# hib register map
Vendor: Texas Instruments
Peripheral module from a debugger description file (folder tm4e1111e6zrb).
Registers are 32-bit, read-write, no defined reset value unless marked. A register's access mark holds for its fields unless they carry their own. Offsets are as the file gives them; lines under a group give offsets from that group; [hi:lo] are bit positions; {n}, {i} and the like mark numbered series; 'fields as' and 'values as' point back to an identical list; <NAME> marks a mode.

## HIB — Hibernation module register addresses
0x00 HIB_RTCC ro — Hibernation RTC Counter
  [31:0] HIB_RTCC — RTC Counter
0x04 HIB_RTCM0 — Hibernation RTC Match 0
  [31:0] HIB_RTCM0 — RTC Match 0
0x0C HIB_RTCLD — Hibernation RTC Load
  [31:0] HIB_RTCLD — RTC Load
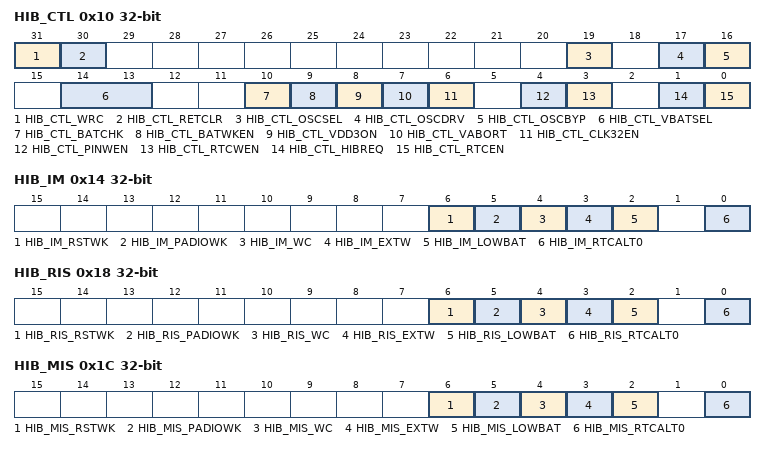
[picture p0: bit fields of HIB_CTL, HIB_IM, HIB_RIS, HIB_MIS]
0x10 HIB_CTL — Hibernation Control
  [31] HIB_CTL_WRC — Write Complete/Capable
  [30] HIB_CTL_RETCLR — GPIO Retention/Clear
  [19] HIB_CTL_OSCSEL — Oscillator Select
  [17] HIB_CTL_OSCDRV — Oscillator Drive Capability
  [16] HIB_CTL_OSCBYP — Oscillator Bypass
  [14:13] HIB_CTL_VBATSEL — Select for Low-Battery Comparator
    0=HIB_CTL_VBATSEL_1_9V (1.9 Volts); 1=HIB_CTL_VBATSEL_2_1V (2.1 Volts (default)); 2=HIB_CTL_VBATSEL_2_3V (2.3 Volts); 3=HIB_CTL_VBATSEL_2_5V (2.5 Volts)
  [10] HIB_CTL_BATCHK — Check Battery Status
  [9] HIB_CTL_BATWKEN — Wake on Low Battery
  [8] HIB_CTL_VDD3ON — VDD Powered
  [7] HIB_CTL_VABORT — Power Cut Abort Enable
  [6] HIB_CTL_CLK32EN — Clocking Enable
  [4] HIB_CTL_PINWEN — External Wake Pin Enable
  [3] HIB_CTL_RTCWEN — RTC Wake-up Enable
  [1] HIB_CTL_HIBREQ — Hibernation Request
  [0] HIB_CTL_RTCEN — RTC Timer Enable
0x14 HIB_IM — Hibernation Interrupt Mask
  [6] HIB_IM_RSTWK — Reset Pad I/O Wake-Up Interrupt Mask
  [5] HIB_IM_PADIOWK — Pad I/O Wake-Up Interrupt Mask
  [4] HIB_IM_WC — External Write Complete/Capable Interrupt Mask
  [3] HIB_IM_EXTW — External Wake-Up Interrupt Mask
  [2] HIB_IM_LOWBAT — Low Battery Voltage Interrupt Mask
  [0] HIB_IM_RTCALT0 — RTC Alert 0 Interrupt Mask
0x18 HIB_RIS ro — Hibernation Raw Interrupt Status
  [6] HIB_RIS_RSTWK — Reset Pad I/O Wake-Up Raw Interrupt Status
  [5] HIB_RIS_PADIOWK — Pad I/O Wake-Up Raw Interrupt Status
  [4] HIB_RIS_WC — Write Complete/Capable Raw Interrupt Status
  [3] HIB_RIS_EXTW — External Wake-Up Raw Interrupt Status
  [2] HIB_RIS_LOWBAT — Low Battery Voltage Raw Interrupt Status
  [0] HIB_RIS_RTCALT0 — RTC Alert 0 Raw Interrupt Status
0x1C HIB_MIS ro — Hibernation Masked Interrupt Status
  [6] HIB_MIS_RSTWK — Reset Pad I/O Wake-Up Interrupt Mask
  [5] HIB_MIS_PADIOWK — Pad I/O Wake-Up Interrupt Mask
  [4] HIB_MIS_WC — Write Complete/Capable Masked Interrupt Status
  [3] HIB_MIS_EXTW — External Wake-Up Masked Interrupt Status
  [2] HIB_MIS_LOWBAT — Low Battery Voltage Masked Interrupt Status
  [0] HIB_MIS_RTCALT0 — RTC Alert 0 Masked Interrupt Status
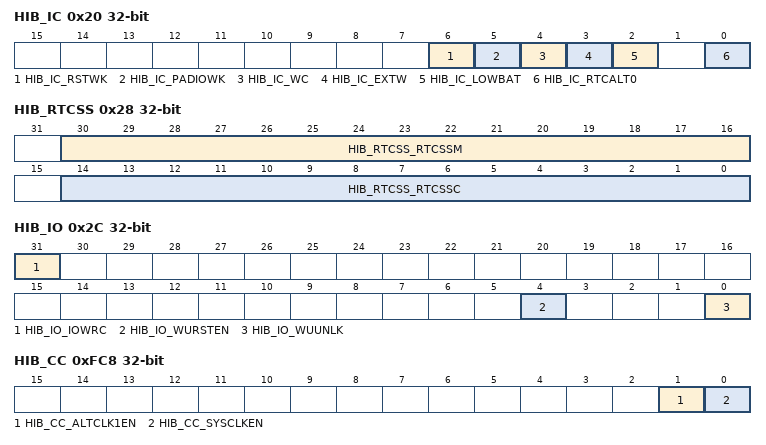
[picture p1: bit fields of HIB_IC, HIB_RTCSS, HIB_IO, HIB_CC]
0x20 HIB_IC — Hibernation Interrupt Clear
  [6] HIB_IC_RSTWK — Reset Pad I/O Wake-Up Interrupt Clear
  [5] HIB_IC_PADIOWK — Pad I/O Wake-Up Interrupt Clear
  [4] HIB_IC_WC — Write Complete/Capable Interrupt Clear
  [3] HIB_IC_EXTW — External Wake-Up Interrupt Clear
  [2] HIB_IC_LOWBAT — Low Battery Voltage Interrupt Clear
  [0] HIB_IC_RTCALT0 — RTC Alert0 Masked Interrupt Clear
0x24 HIB_RTCT — Hibernation RTC Trim
  [15:0] HIB_RTCT_TRIM — RTC Trim Value
0x28 HIB_RTCSS — Hibernation RTC Sub Seconds
  [30:16] HIB_RTCSS_RTCSSM — RTC Sub Seconds Match
  [14:0] HIB_RTCSS_RTCSSC — RTC Sub Seconds Count
0x2C HIB_IO — Hibernation IO Configuration
  [31] HIB_IO_IOWRC — I/O Write Complete
  [4] HIB_IO_WURSTEN — Reset Wake Source Enable
  [0] HIB_IO_WUUNLK — I/O Wake Pad Configuration Enable
0x30 HIB_DATA — Hibernation Data
  [31:0] HIB_DATA_RTD — Hibernation Module NV Data
0xFC8 HIB_CC — Hibernation Clock Control
  [1] HIB_CC_ALTCLK1EN — Alternate Clock 1 Enable
  [0] HIB_CC_SYSCLKEN — RTCOSC to System Clock Enable
